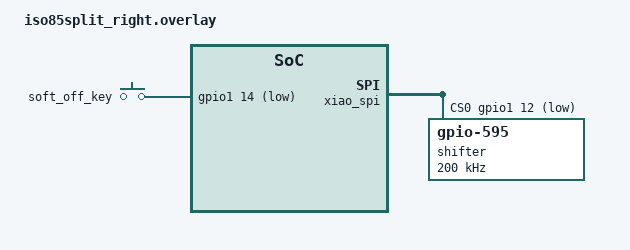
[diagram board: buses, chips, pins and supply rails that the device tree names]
#include "iso85split.dtsi"

&xiao_serial {status="disabled";};

&xiao_spi {
    status="okay";
    cs-gpios = <&gpio1 12 (GPIO_ACTIVE_LOW)>;
    shifter: 595@0 {
        compatible = "zmk,gpio-595";
        status="okay";
        gpio-controller;
        spi-max-frequency=<200000>;
        reg = <0>;
        #gpio-cells=<2>;
        ngpios=<8>;
    };
};

&default_transform {
    col-offset = <6>;
};

&kscan0 {
    wakeup-source;
    col-gpios = <&gpio1 11 (GPIO_ACTIVE_HIGH)>,
                <&gpio0 9 (GPIO_ACTIVE_HIGH)>,
                <&gpio0 10 (GPIO_ACTIVE_HIGH)>,
                <&shifter 7 (GPIO_ACTIVE_HIGH)>,
                <&shifter 0 (GPIO_ACTIVE_HIGH)>,
                <&shifter 1 (GPIO_ACTIVE_HIGH)>,
                <&shifter 2 (GPIO_ACTIVE_HIGH)>,
                <&shifter 4 (GPIO_ACTIVE_HIGH)>,
                <&shifter 3 (GPIO_ACTIVE_HIGH)>,
                <&shifter 6 (GPIO_ACTIVE_HIGH)>
                ;
};

&soft_off_key {
    gpios = <&gpio1 14 (GPIO_ACTIVE_LOW | GPIO_PULL_UP)>;
};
